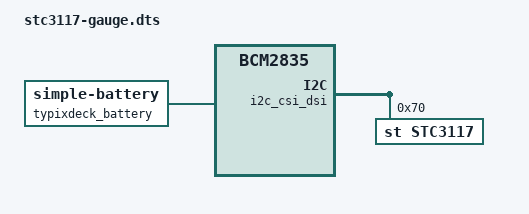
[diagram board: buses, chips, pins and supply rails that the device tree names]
// TypixDeck 0720: STC3117 fuel gauge (U53, 0x70) on the compute module's
// SDA0/SCL0 pair. The gauge sits behind the Pi/ESP I2C mux (U70) and is only
// reachable while MUX_SEL=0 (Pi side, the power-on default).
//
// Bus target (verified on CM4, Pi OS 6.18 - the two labels are NOT the same
// node there, see CLAUDE.md "CM_SDA0/SCL0 != GPIO0/1"):
//   CM4: &i2c_csi_dsi  = /soc/i2c0mux/i2c@1 (GPIO44/45, Linux i2c-10)  <- default
//        &i2c_csi_dsi0 = /soc/i2c0mux/i2c@0 (= i2c_vc, GPIO0/1) - owned by the
//        DPI panel; selecting it fails with "pin gpio0 already requested".
//   CM5: &i2c_csi_dsi0 = RP1 I2C on GPIO38/39 -> pass the i2c_csi_dsi0 param.
// config.txt (same split the i2c-fan overlay uses on this board):
//   [cm4] dtoverlay=stc3117-gauge
//   [cm5] dtoverlay=stc3117-gauge,i2c_csi_dsi0
//
// Board parameters: sense resistor U37 = 10 mOhm (BOM); battery 604070
// LiPo ~2400 mAh. ALM pin goes to the ESP32-S3 IO expander, not the Pi,
// so no interrupt is wired here (driver polls).
/dts-v1/;
/plugin/;

/ {
	compatible = "brcm,bcm2835";

	fragment@0 {
		target-path = "/";
		__overlay__ {
			typixdeck_battery: typixdeck-battery {
				compatible = "simple-battery";
				device-chemistry = "lithium-ion-polymer";
				charge-full-design-microamp-hours = <2400000>;
				voltage-min-design-microvolt = <3000000>;
				voltage-max-design-microvolt = <4200000>;
			};
		};
	};

	frag1: fragment@1 {
		target = <&i2c_csi_dsi>;
		__overlay__ {
			#address-cells = <1>;
			#size-cells = <0>;
			status = "okay";

			stc3117: fuel-gauge@70 {
				compatible = "st,stc3117";
				reg = <0x70>;
				monitored-battery = <&typixdeck_battery>;
				shunt-resistor-micro-ohms = <10000>;
				status = "okay";
			};
		};
	};

	__overrides__ {
		i2c_csi_dsi0 = <&frag1>,"target:0=",<&i2c_csi_dsi0>;
		capacity-uah = <&typixdeck_battery>,"charge-full-design-microamp-hours:0";
		shunt-uohm = <&stc3117>,"shunt-resistor-micro-ohms:0";
	};
};
